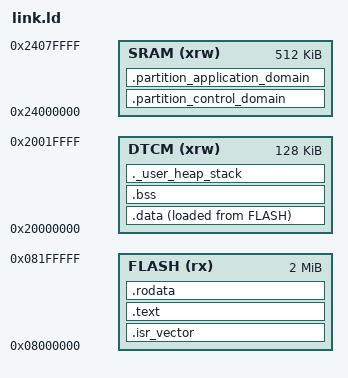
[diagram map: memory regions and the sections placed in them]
/*
 * AUTO-GENERATED by maxrtos_codegen -- DO NOT EDIT BY HAND.
 * Source: tools/maxrtos_codegen/examples/example_module.json
 *
 * This file lays out kernel memory and one NOLOAD section per partition
 * MPU domain, which holds all of that partition's process stacks.
 * Board-specific sections (isr vector table contents, heap/stack sizes for
 * the main stack, etc.) belong in the board's own linker fragment.
 */

ENTRY(Reset_Handler)

MEMORY
{
    FLASH      (rx) : ORIGIN = 0x08000000, LENGTH = 2097152
    DTCM       (xrw) : ORIGIN = 0x20000000, LENGTH = 131072
    SRAM       (xrw) : ORIGIN = 0x24000000, LENGTH = 524288
}

SECTIONS
{
    .isr_vector :
    {
        . = ALIGN(4);
        __isr_vector_start = .;
        KEEP(*(.isr_vector))
        . = ALIGN(4);
    } >FLASH

    .text :
    {
        . = ALIGN(4);
        *(.text)
        *(.text*)
        . = ALIGN(4);
        _etext = .;
    } >FLASH

    .rodata :
    {
        . = ALIGN(4);
        *(.rodata)
        *(.rodata*)
        . = ALIGN(4);
    } >FLASH

    _sidata = LOADADDR(.data);
    .data :
    {
        . = ALIGN(4);
        _sdata = .;
        *(.data)
        *(.data*)
        . = ALIGN(4);
        _edata = .;
    } >DTCM AT>FLASH

    .bss :
    {
        . = ALIGN(4);
        _sbss = .;
        __bss_start__ = _sbss;
        *(.bss)
        *(.bss*)
        *(COMMON)
        . = ALIGN(4);
        _ebss = .;
        __bss_end__ = _ebss;
    } >DTCM

    ._user_heap_stack :
    {
        . = ALIGN(8);
        PROVIDE(end = .);
        PROVIDE(_end = .);
        . = . + _Min_Heap_Size;
        . = . + _Min_Stack_Size;
        . = ALIGN(8);
    } >DTCM

    /* Partition MPU domains packed into SRAM, in partition-id order.
     * Each domain holds all of its partition's process stacks and is aligned
     * and padded to its own power-of-two size so one MPU region covers it. */
    .partition_control_domain (NOLOAD) :
    {
        . = ALIGN(512);
        __partition_control_domain_start = .;
        *(.partition_control_control_main_stack)
        /* Pad to the domain size. If the stacks overflowed it, ld fails
         * here with "cannot move location counter backwards". */
        . = __partition_control_domain_start + 512;
    } >SRAM
    .partition_application_domain (NOLOAD) :
    {
        . = ALIGN(512);
        __partition_application_domain_start = .;
        *(.partition_application_application_main_stack)
        /* Pad to the domain size. If the stacks overflowed it, ld fails
         * here with "cannot move location counter backwards". */
        . = __partition_application_domain_start + 512;
    } >SRAM
    .ARM.attributes 0 : { *(.ARM.attributes) }
}

/* Main/interrupt stack: top of the kernel memory region. */
__StackTop = ORIGIN(DTCM) + LENGTH(DTCM);
_Min_Heap_Size = 0x200;
_Min_Stack_Size = 0x400;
